# AC78xx register map
Vendor: AutoChips; Series: AC78xx; File version: 1.0
CPU: CM3 r2p1, little endian, MPU, no FPU, 3 interrupt priority bits
Registers are 32-bit, read-write, no defined reset value unless marked. A register's access mark holds for its fields unless they carry their own. Offsets are from the block's base; [hi:lo] are bit positions.

## SPI1 — Serial Peripheral Interface
Base 0x4000C000; register names take the prefix SPI1_
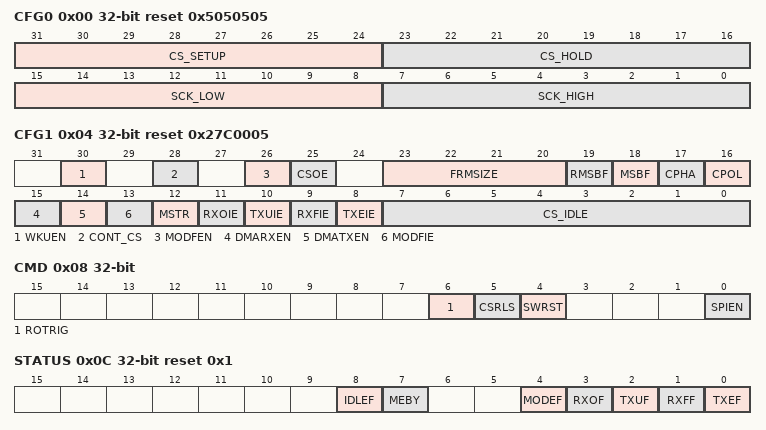
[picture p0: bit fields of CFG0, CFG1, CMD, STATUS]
0x00 CFG0 reset 0x5050505 — SPI Configuration Register 0
  [31:24] CS_SETUP — CS Setup Count
  [23:16] CS_HOLD — CS hold Count
  [15:8] SCK_LOW — SCK Low Count
  [7:0] SCK_HIGH — SCK High Count
0x04 CFG1 reset 0x27C0005 — SPI Configuration Register 1
  [30] WKUEN — wake up function enable(only valid for slave mode)
  [28] CONT_CS — CS continuous output enable
  [26] MODFEN — mode fault detect enable
  [25] CSOE — CS hardware output enable
  [23:20] FRMSIZE — frame size
  [19] RMSBF — RX MSB first Select
  [18] MSBF — TX MSB first Select
  [17] CPHA — clock phase
    0=the second SCK transition is the first data capture edge; 1=the first SCK transition is the first data capture edge
  [16] CPOL — clock polarity
    0=SCK is 0 when idle; 1=SCK is 1 when idle
  [15] DMARXEN — DMA RX channel enable
  [14] DMATXEN — DMA TX channel enable
  [13] MODFIE — mode fault interrupt enable
  [12] MSTR — master/slave mode selection
    0=slave mode; 1=master mode
  [11] RXOIE — RX buffer overflow interrupt enable
  [10] TXUIE — TX buffer underflow interrupt enable
  [9] RXFIE
  [8] TXEIE — TX buffer empty interrupt enable
  [7:0] CS_IDLE — CS idle count
0x08 CMD — SPI Command Register
  [6] ROTRIG — Master RX only mode trigger
  [5] CSRLS — CS release(only valid for CS continuous output)
  [4] SWRST — software reset
  [0] SPIEN — SPI Enable
0x0C STATUS reset 0x1 — SPI Status Register
  [8] IDLEF — SPI IDLE flag
  [7] MEBY — SPI master engine busy flag
  [4] MODEF — Mode error flag
  [3] RXOF — RX buffer overflow flag
  [2] TXUF — TX buffer underflow flag
  [1] RXFF — RX buffer Full flag
  [0] TXEF — TX buffer empty flag
0x10 DATA reset 0x0 — SPI Data Register
  [15:0] DATA
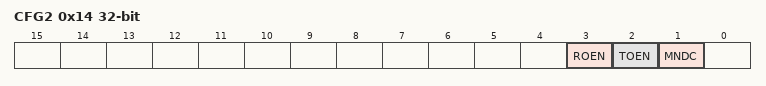
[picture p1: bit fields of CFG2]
0x14 CFG2 — SPI configuration register 2
  [3] ROEN — RX only mode enable bit
  [2] TOEN — TX only mode enable bit
  [1] MNDC — Master No Overflow mode enable bit

## SPI2 — Serial Peripheral Interface
Base 0x4000D000; register names take the prefix SPI2_
Registers as SPI1.

## I2C1 — Inter-Integrated Circuit
Base 0x4000E000; register names take the prefix I2C1_
0x00 ADDR1 reset 0x0 — I2C Address Register 1
  [7:1] AD — Address
0x04 ADDR2 reset 0x0 — I2C ADDR register 2
  [2:0] AD — Address
0x08 SAMPLE_CNT reset 0x0 — I2C SAMPLE CNT Register
  [7:0] SAMPLE_CNT_DIV — Adjust the width of each sample
0x0C STEP_CNT reset 0x4 — I2C STEP CNT Register
  [7:0] STEP_CNT_DIV — Specifies the number of Samples per half pulse width
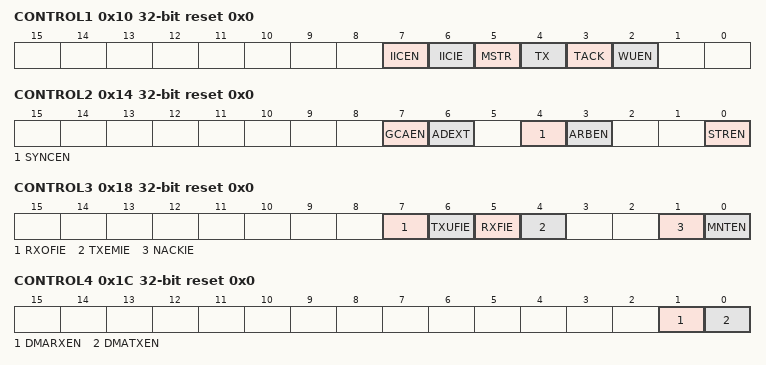
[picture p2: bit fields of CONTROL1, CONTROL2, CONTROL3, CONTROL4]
0x10 CONTROL1 reset 0x0 — I2C Control Register 1
  [7] IICEN — I2C Module Enable
  [6] IICIE — I2C interrupt Enable
  [5] MSTR — I2C operation mode Select
    0=Slave Mode; 1=Master Mode
  [4] TX — Transmit Mode Select(valid for master)
  [3] TACK — Transmit Acknowledge Enable
    0=ACK will sent to the bus on the following receiving byte; 1=NACK will sent to the bus on the following receiving byte
  [2] WUEN — wakeup enable
0x14 CONTROL2 reset 0x0 — I2C Control Register 2
  [7] GCAEN — General Call enable(valid for Slave)
  [6] ADEXT — Address Extension(valid for Slave)
  [4] SYNCEN — SCL Sync Enable
  [3] ARBEN — Arbitration Enable
  [0] STREN — SCL Strech enable(Valid for slave)
0x18 CONTROL3 reset 0x0 — I2C Control Register 3
  [7] RXOFIE — RX buffer overflow interrupt enable
  [6] TXUFIE — TX buffer underflow error interrupt enable
  [5] RXFIE — RX buffer full interrupt enable
  [4] TXEMIE — TX buffer empty interrupt enable
  [1] NACKIE — NACK get interrupt Enable
  [0] MNTEN — Monitor Function Enable
0x1C CONTROL4 reset 0x0 — I2C Control Register 4
  [1] DMARXEN — DMARX enable
  [0] DMATXEN — DMATX enable
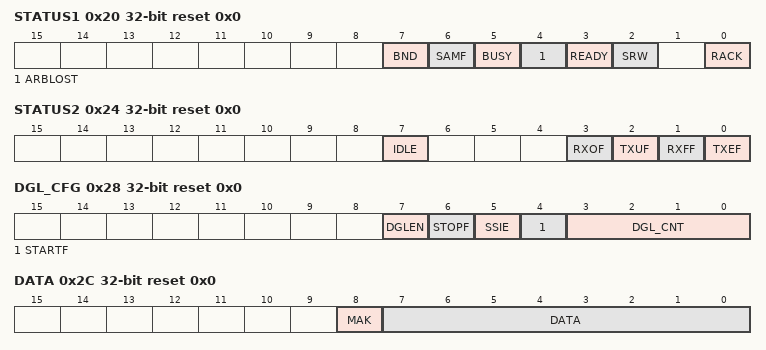
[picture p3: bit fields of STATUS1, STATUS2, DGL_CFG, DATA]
0x20 STATUS1 reset 0x0 — I2C Status Register 1
  [7] BND ro — Byte end flag
  [6] SAMF — Address match
  [5] BUSY ro — indicates the status of the bus regardless of slave or master mode
  [4] ARBLOST — Arbitration lost flag
  [3] READY ro — internal hardware core is ready for new command or not
  [2] SRW ro — Slave read/write
  [0] RACK ro — Acknowledge received(master or Slave TX mode)
0x24 STATUS2 reset 0x0 — I2C Status Register 2
  [7] IDLE ro — I2C Core Hardware state
  [3] RXOF ro — RX buffer overflow flag(only valid for slave)
  [2] TXUF ro — TX buffer underflow flag(only valid for slave)
  [1] RXFF — RX buffer Full flag(only valid for slave)
  [0] TXEF — TX buffer empty flag(only valid for slave)
0x28 DGL_CFG reset 0x0 — I2C Deglitch Configuration Register
  [7] DGLEN — I2C Deglitch filter Enable
  [6] STOPF — I2C Bus Stop detect Flag
  [5] SSIE — I2C Bus STOP or START interrupt Enable
  [4] STARTF — I2C Bus Start Detect Flag
  [3:0] DGL_CNT — Deglitch Counter
0x2C DATA reset 0x0 — I2C Data Register
  [8] MAK ro — Slave Monitor Function ACK bit
  [7:0] DATA
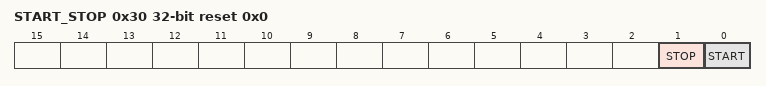
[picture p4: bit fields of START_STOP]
0x30 START_STOP reset 0x0 — I2C START_STOP Register
  [1] STOP — I2C Stop(valid for master)
  [0] START — I2C Start(valid for master)

## I2C2 — Inter-Integrated Circuit
Base 0x4000F000; register names take the prefix I2C2_
Registers as I2C1.
